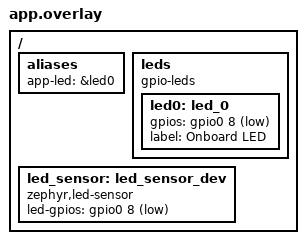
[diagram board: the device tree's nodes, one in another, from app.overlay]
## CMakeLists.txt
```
cmake_minimum_required(VERSION 3.20.0)

list(APPEND DTS_ROOT "${CMAKE_CURRENT_SOURCE_DIR}/..")

find_package(Zephyr REQUIRED HINTS $ENV{ZEPHYR_BASE})
project(led_sensor_app)

zephyr_include_directories("${CMAKE_CURRENT_SOURCE_DIR}/../include")

add_subdirectory("${CMAKE_CURRENT_SOURCE_DIR}/../drivers" drivers)
target_sources(app PRIVATE src/main.cpp)
```

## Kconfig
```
# Source base Zephyr Kconfig tree
source "$(ZEPHYR_BASE)/Kconfig"

# Source out-of-tree LED sensor driver Kconfig
rsource "../drivers/sensor/led_sensor/Kconfig"

menu "Application Configuration"

menuconfig LED_SUBSYSTEM
bool "LED Subsystem"
default y
help
  Enable the LED subsystem configuration options.

config APP_HEARTBEAT_PERIOD_MS
int "Heartbeat period in ms"
depends on LED_SUBSYSTEM
default 500
range 100 2000
help
  Period between LED heartbeat toggles in milliseconds.

config LED_BRIGHTNESS
int "LED brightness (%)"
depends on LED_SUBSYSTEM
default 50
range 0 100
help
  Brightness percentage for the LED (0 to 100).

config LED_FADE_DURATION
int "LED fade duration (ms)"
depends on LED_SUBSYSTEM
default 1000
range 0 5000
help
  Duration of the LED fade cycle in milliseconds (0 to 5000 ms).

menuconfig ADVANCED_LED_SETTINGS
bool "Advanced LED settings"
depends on LED_SUBSYSTEM
help
  Enable advanced configuration options for LEDs.

menu "Expert settings"
visible if ADVANCED_LED_SETTINGS

config LED_DEBUG
bool "Enable LED debugging"
help
  Enable debug logs and features for the LED driver.

config LED_CUSTOM_BLINK_PATTERN
bool "Enable custom blink pattern"
help
  Enable custom programmable blinking sequences.
endmenu

endmenu
```

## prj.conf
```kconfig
CONFIG_CPP=y
CONFIG_STD_CPP17=y
CONFIG_REQUIRES_FULL_LIBC=y

CONFIG_GPIO=y
CONFIG_SENSOR=y
CONFIG_LED_SENSOR=y

CONFIG_SERIAL=y
CONFIG_CONSOLE=y
CONFIG_UART_CONSOLE=y

# Shell configuration
CONFIG_SHELL=y
CONFIG_SHELL_BACKEND_SERIAL=y
CONFIG_SHELL_PROMPT_UART="zephyr:~$ "

CONFIG_LOG=y
CONFIG_SENSOR_LOG_LEVEL_INF=y
```

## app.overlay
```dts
/ {
aliases {
app-led = &led0;
};

leds {
compatible = "gpio-leds";
led0: led_0 {
gpios = <&gpio0 8 GPIO_ACTIVE_LOW>;
label = "Onboard LED";
};
};

led_sensor: led_sensor_dev {
compatible = "zephyr,led-sensor";
led-gpios = <&gpio0 8 GPIO_ACTIVE_LOW>;
status = "okay";
};
};
```

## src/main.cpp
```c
#include <zephyr/kernel.h>
#include <zephyr/drivers/gpio.h>
#include <zephyr/logging/log.h>

LOG_MODULE_REGISTER(main, CONFIG_LOG_DEFAULT_LEVEL);

/* Get LED spec from devicetree alias app_led */
#define LED_NODE DT_ALIAS(app_led)

static const struct gpio_dt_spec led = GPIO_DT_SPEC_GET(LED_NODE, gpios);

int main(void)
{
    int ret;

    if (!gpio_is_ready_dt(&led)) {
        return 0;
    }

    ret = gpio_pin_configure_dt(&led, GPIO_OUTPUT_ACTIVE);
    if (ret < 0) {
        return 0;
    }

    LOG_INF("Starting LED heartbeat with period %d ms using app_led alias", CONFIG_APP_HEARTBEAT_PERIOD_MS);

    while (1) {
        ret = gpio_pin_toggle_dt(&led);
        if (ret < 0) {
            return 0;
        }
        k_msleep(CONFIG_APP_HEARTBEAT_PERIOD_MS);
    }
}
```
